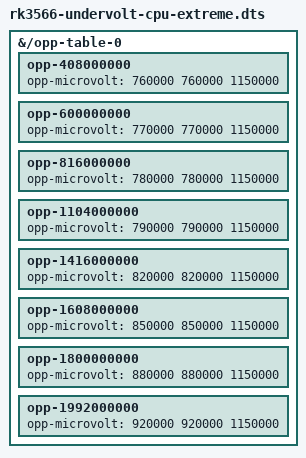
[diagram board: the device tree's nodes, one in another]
/*
 * RK3566 Extreme CPU Undervolt
 *
 * Aggressive voltage curve from the same 10M+ sample profiling
 * campaign (external USB-PD measurement + SCMI I2C telemetry,
 * R statistical analysis). Pushes ~20mV below the optimal curve
 * at each OPP based on observed stability margins.
 *
 * Silicon-dependent — not all chips are stable at these voltages.
 * Test under sustained load before relying on this curve.
 */
/dts-v1/;
/plugin/;

/ {
fragment@0 {
	target-path = "/opp-table-0";
	__overlay__ {
		opp-408000000  { opp-microvolt = <760000 760000 1150000>; };
		opp-600000000  { opp-microvolt = <770000 770000 1150000>; };
		opp-816000000  { opp-microvolt = <780000 780000 1150000>; };
		opp-1104000000 { opp-microvolt = <790000 790000 1150000>; };
		opp-1416000000 { opp-microvolt = <820000 820000 1150000>; };
		opp-1608000000 { opp-microvolt = <850000 850000 1150000>; };
		opp-1800000000 { opp-microvolt = <880000 880000 1150000>; };
		opp-1992000000 { opp-microvolt = <920000 920000 1150000>; };
	};
};
};
